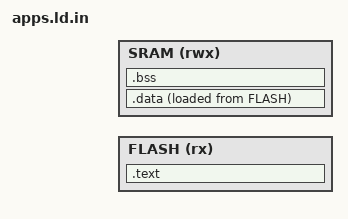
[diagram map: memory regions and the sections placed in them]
ENTRY(_init);

MEMORY
{
    FLASH (rx) : ORIGIN = __FLASH_ORIGIN + __KFLASHMEM_SIZE, LENGTH = __AFLASHMEM_SIZE
    SRAM (rwx) : ORIGIN = (__RAM_BASE + __KRAMMEM_SIZE), LENGTH = __AMEM_SIZE
}

SECTIONS
{
    .text :
    {
        KEEP(*(.init*))
        *(.text*)
        *(.rodata*)
    } > FLASH
 
    .data :
    {
        apps_etext = LOADADDR(.data);
        apps_data = .;
        *(vtable)
        *(.data*)
        apps_edata = .;
    } > SRAM AT > FLASH
 
    .bss :
    {
        __bss_start__ = .;
        apps_bss = .;
        *(.bss*)
        *(COMMON)
        . = ALIGN(32 / 8);
        apps_ebss = .;
        __bss_end__ = .;
    } > SRAM

    /* NOTE: .fini, .rodata, .eh_frame, .init_array not a separate section */
}
